# cc13x2_cc26x2 register map
File version: 2.1
CPU: CM4 r0p1, little endian, MPU, FPU, 3 interrupt priority bits
Registers are 32-bit, read-write, reset 0x0 unless marked. A register's access mark holds for its fields unless they carry their own. Offsets are from the block's base; [hi:lo] are bit positions; {n}, {i} and the like mark numbered series; 'fields as' and 'values as' point back to an identical list.

## PRCM — Power, Reset and Clock Management
Base 0x40082000
0x00 INFRCLKDIVR — Infrastructure Clock Division Factor For Run Mode
  [1:0] RATIO
0x04 INFRCLKDIVS — Infrastructure Clock Division Factor For Sleep Mode
  [1:0] RATIO
0x08 INFRCLKDIVDS — Infrastructure Clock Division Factor For DeepSleep Mode
  [1:0] RATIO
0x0C VDCTL — MCU Voltage Domain Control
  [0] ULDO
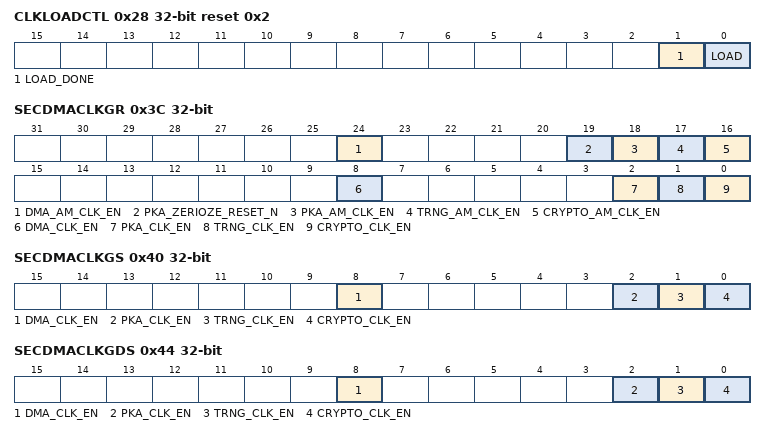
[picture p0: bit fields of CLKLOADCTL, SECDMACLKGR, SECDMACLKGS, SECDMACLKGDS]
0x28 CLKLOADCTL reset 0x2 — Load PRCM Settings To CLKCTRL Power Domain
  [1] LOAD_DONE, [0] LOAD
0x2C RFCCLKG reset 0x1 — RFC Clock Gate
  [0] CLK_EN
0x30 VIMSCLKG reset 0x3 — VIMS Clock Gate
  [1:0] CLK_EN
0x3C SECDMACLKGR — SEC (PKA And TRNG And CRYPTO) And UDMA Clock Gate For Run And All Modes
  [24] DMA_AM_CLK_EN, [19] PKA_ZERIOZE_RESET_N, [18] PKA_AM_CLK_EN, [17] TRNG_AM_CLK_EN, [16] CRYPTO_AM_CLK_EN, [8] DMA_CLK_EN, [2] PKA_CLK_EN, [1] TRNG_CLK_EN, [0] CRYPTO_CLK_EN
0x40 SECDMACLKGS — SEC (PKA And TRNG And CRYPTO) And UDMA Clock Gate For Sleep Mode
  [8] DMA_CLK_EN, [2] PKA_CLK_EN, [1] TRNG_CLK_EN, [0] CRYPTO_CLK_EN
0x44 SECDMACLKGDS — SEC (PKA And TRNG and CRYPTO) And UDMA Clock Gate For Deep Sleep Mode
  [8] DMA_CLK_EN, [2] PKA_CLK_EN, [1] TRNG_CLK_EN, [0] CRYPTO_CLK_EN
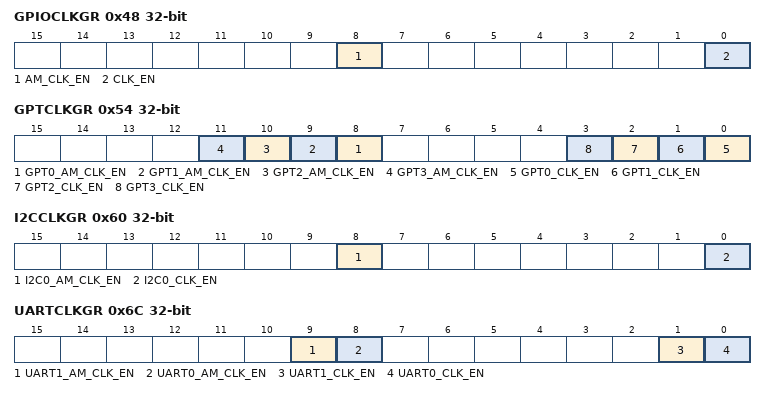
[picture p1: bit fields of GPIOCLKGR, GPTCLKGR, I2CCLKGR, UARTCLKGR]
0x48 GPIOCLKGR — GPIO Clock Gate For Run And All Modes
  [8] AM_CLK_EN, [0] CLK_EN
0x4C GPIOCLKGS — GPIO Clock Gate For Sleep Mode
  [0] CLK_EN
0x50 GPIOCLKGDS — GPIO Clock Gate For Deep Sleep Mode
  [0] CLK_EN
0x54 GPTCLKGR — GPT Clock Gate For Run And All Modes
  [n+8] GPT{n}_AM_CLK_EN (n=0..3) — Enable clock for GPT{n} in all modes
  [n] GPT{n}_CLK_EN (n=0..3) — Enable clock for GPT{n}
0x58 GPTCLKGS — GPT Clock Gate For Sleep Mode
  [3:0] CLK_EN
0x5C GPTCLKGDS — GPT Clock Gate For Deep Sleep Mode
  [3:0] CLK_EN
0x60 I2CCLKGR — I2C Clock Gate For Run And All Modes
  [8] I2C0_AM_CLK_EN — Enable clock for I2C0 for all modes
  [0] I2C0_CLK_EN — Enable clock for I2C0
0x64 I2CCLKGS — I2C Clock Gate For Sleep Mode
  [0] CLK_EN
0x68 I2CCLKGDS — I2C Clock Gate For Deep Sleep Mode
  [0] CLK_EN
0x6C UARTCLKGR — UART Clock Gate For Run And All Modes
  [9] UART1_AM_CLK_EN — Enable clock for UART1 for all modes
  [8] UART0_AM_CLK_EN — Enable clock for UART0 for all modes
  [1] UART1_CLK_EN — Enable clock for UART1
  [0] UART0_CLK_EN — Enable clock for UART0
0x70 UARTCLKGS — UART Clock Gate For Sleep Mode
  [1:0] CLK_EN
0x74 UARTCLKGDS — UART Clock Gate For Deep Sleep Mode
  [1:0] CLK_EN
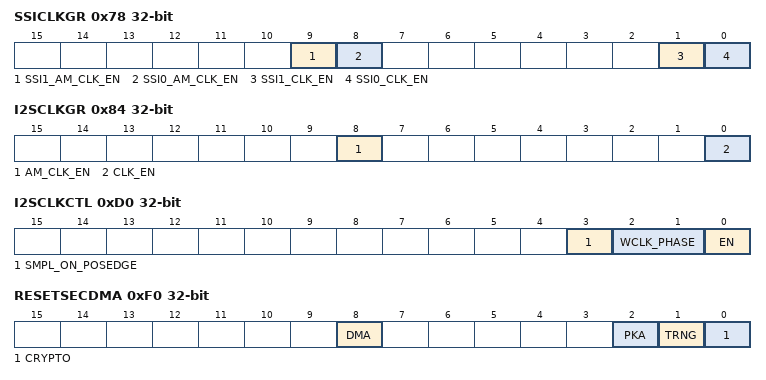
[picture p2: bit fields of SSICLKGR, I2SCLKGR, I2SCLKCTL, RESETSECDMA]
0x78 SSICLKGR — SSI Clock Gate For Run And All Modes
  [9] SSI1_AM_CLK_EN — Enable clock for SSI1 for all modes
  [8] SSI0_AM_CLK_EN — Enable clock for SSI0 for all modes
  [1] SSI1_CLK_EN — Enable clock for SSI1
  [0] SSI0_CLK_EN — Enable clock for SSI0
0x7C SSICLKGS — SSI Clock Gate For Sleep Mode
  [1:0] CLK_EN
0x80 SSICLKGDS — SSI Clock Gate For Deep Sleep Mode
  [1:0] CLK_EN
0x84 I2SCLKGR — I2S Clock Gate For Run And All Modes
  [8] AM_CLK_EN, [0] CLK_EN
0x88 I2SCLKGS — I2S Clock Gate For Sleep Mode
  [0] CLK_EN
0x8C I2SCLKGDS — I2S Clock Gate For Deep Sleep Mode
  [0] CLK_EN
0xB4 SYSBUSCLKDIV — Internal. Only to be used through TI provided API.
  [2:0] RATIO
0xB8 CPUCLKDIV — Internal. Only to be used through TI provided API.
  [0] RATIO
0xBC PERBUSCPUCLKDIV — Internal. Only to be used through TI provided API.
  [3:0] RATIO
0xC4 PERDMACLKDIV — Internal. Only to be used through TI provided API.
  [3:0] RATIO
0xC8 I2SBCLKSEL — I2S Clock Control
  [0] SRC
0xCC GPTCLKDIV — GPT Scalar
  [3:0] RATIO
0xD0 I2SCLKCTL — I2S Clock Control
  [3] SMPL_ON_POSEDGE, [2:1] WCLK_PHASE, [0] EN
0xD4 I2SMCLKDIV — MCLK Division Ratio
  [9:0] MDIV
0xD8 I2SBCLKDIV — BCLK Division Ratio
  [9:0] BDIV
0xDC I2SWCLKDIV — WCLK Division Ratio
  [15:0] WDIV
0xF0 RESETSECDMA — RESET For SEC (PKA And TRNG And CRYPTO) And UDMA
  [8] DMA, [2] PKA, [1] TRNG, [0] CRYPTO
0xF4 RESETGPIO — RESET For GPIO IPs
  [0] GPIO
0xF8 RESETGPT — RESET For GPT Ips
  [0] GPT
0xFC RESETI2C — RESET For I2C IPs
  [0] I2C
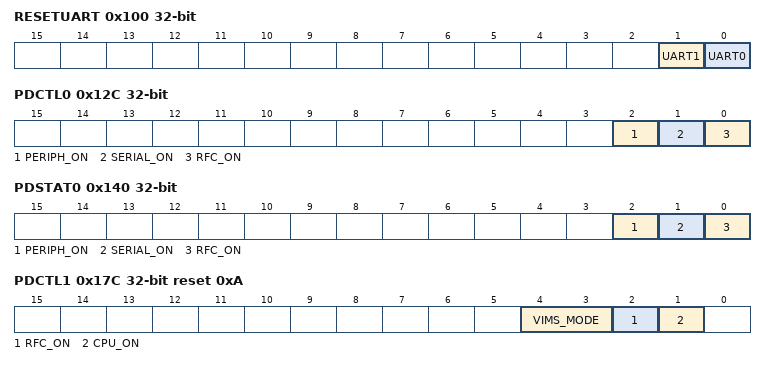
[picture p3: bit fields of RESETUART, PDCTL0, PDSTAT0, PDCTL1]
0x100 RESETUART — RESET For UART IPs
  [1] UART1, [0] UART0
0x104 RESETSSI — RESET For SSI IPs
  [1:0] SSI
0x108 RESETI2S — RESET For I2S IP
  [0] I2S
0x12C PDCTL0 — Power Domain Control
  [2] PERIPH_ON, [1] SERIAL_ON, [0] RFC_ON
0x130 PDCTL0RFC — RFC Power Domain Control
  [0] ON
0x134 PDCTL0SERIAL — SERIAL Power Domain Control
  [0] ON
0x138 PDCTL0PERIPH — PERIPH Power Domain Control
  [0] ON
0x140 PDSTAT0 ro — Power Domain Status
  [2] PERIPH_ON, [1] SERIAL_ON, [0] RFC_ON
0x144 PDSTAT0RFC ro — RFC Power Domain Status
  [0] ON
0x148 PDSTAT0SERIAL ro — SERIAL Power Domain Status
  [0] ON
0x14C PDSTAT0PERIPH ro — PERIPH Power Domain Status
  [0] ON
0x17C PDCTL1 reset 0xA — Power Domain Control
  [4:3] VIMS_MODE
    0=CPU_DEP (VIMS power domain is only powered when CPU power domain is powered.); 1=BUS_DEP (VIMS power domain is powered whenever the BUS power domain is powered.); 0b1x=BLOCKED (Block power up of VIMS power domain at next wake up. This mode only has effect when VIMS power domain is not powered. Used for Autonomous RF Core.)
  [2] RFC_ON
  [1] CPU_ON
0x184 PDCTL1CPU reset 0x1 — CPU Power Domain Direct Control
  [0] ON
0x188 PDCTL1RFC — RFC Power Domain Direct Control
  [0] ON
0x18C PDCTL1VIMS reset 0x1 — VIMS Mode Direct Control
  [1:0] MODE
    values as PDCTL1.VIMS_MODE
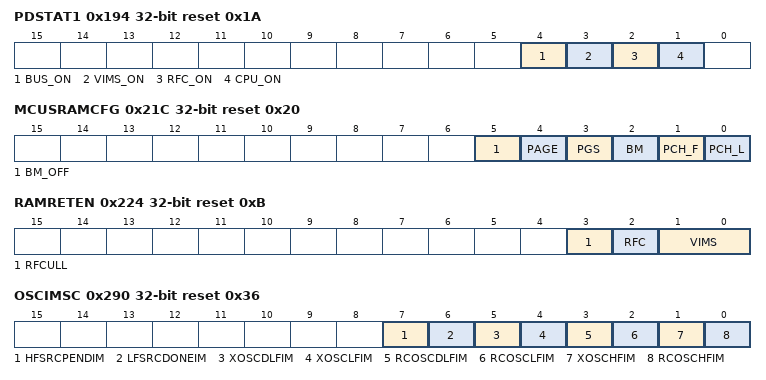
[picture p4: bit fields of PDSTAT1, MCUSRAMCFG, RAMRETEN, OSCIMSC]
0x194 PDSTAT1 ro reset 0x1A — Power Manager Status
  [4] BUS_ON, [3] VIMS_ON, [2] RFC_ON, [1] CPU_ON
0x198 PDSTAT1BUS ro reset 0x1 — BUS Power Domain Direct Read Status
  [0] ON
0x19C PDSTAT1RFC ro — RFC Power Domain Direct Read Status
  [0] ON
0x1A0 PDSTAT1CPU ro reset 0x1 — CPU Power Domain Direct Read Status
  [0] ON
0x1A4 PDSTAT1VIMS ro reset 0x1 — VIMS Mode Direct Read Status
  [0] ON
0x1CC RFCBITS — Control To RFC
  [31:0] READ
0x1D0 RFCMODESEL — Selected RFC Mode
  [2:0] CURR
0x1D4 RFCMODEHWOPT ro — Allowed RFC Modes
  [7:0] AVAIL
0x1E0 PWRPROFSTAT reset 0x1 — Power Profiler Register
  [7:0] VALUE
0x21C MCUSRAMCFG reset 0x20 — MCU SRAM configuration
  [5] BM_OFF, [4] PAGE, [3] PGS, [2] BM, [1] PCH_F, [0] PCH_L
0x224 RAMRETEN reset 0xB — Memory Retention Control
  [3] RFCULL, [2] RFC, [1:0] VIMS
0x290 OSCIMSC reset 0x36 — Oscillator Interrupt Mask
  [7] HFSRCPENDIM, [6] LFSRCDONEIM, [5] XOSCDLFIM, [4] XOSCLFIM, [3] RCOSCDLFIM, [2] RCOSCLFIM, [1] XOSCHFIM, [0] RCOSCHFIM
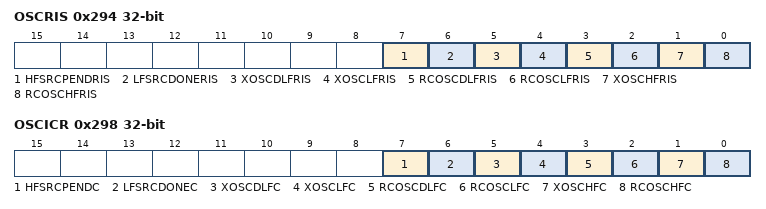
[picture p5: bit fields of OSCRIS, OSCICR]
0x294 OSCRIS ro — Oscillator Raw Interrupt Status
  [7] HFSRCPENDRIS, [6] LFSRCDONERIS, [5] XOSCDLFRIS, [4] XOSCLFRIS, [3] RCOSCDLFRIS, [2] RCOSCLFRIS, [1] XOSCHFRIS, [0] RCOSCHFRIS
0x298 OSCICR wo — Oscillator Raw Interrupt Clear
  [7] HFSRCPENDC, [6] LFSRCDONEC, [5] XOSCDLFC, [4] XOSCLFC, [3] RCOSCDLFC, [2] RCOSCLFC, [1] XOSCHFC, [0] RCOSCHFC
